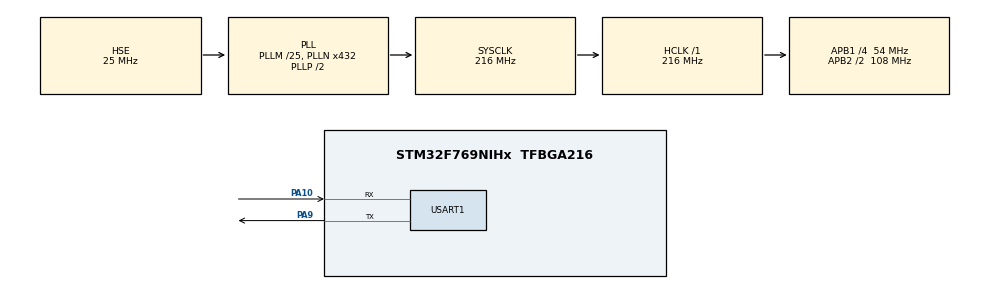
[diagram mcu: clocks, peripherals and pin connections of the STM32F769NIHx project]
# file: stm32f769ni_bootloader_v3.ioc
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Mcu.Family=STM32F7
Mcu.Name=STM32F769NIHx
Mcu.Package=TFBGA216
NVIC.PriorityGroup=NVIC_PRIORITYGROUP_4
NVIC.USART1_IRQn=true\:15\:0\:true\:false\:true\:true\:true
PA10.Mode=Asynchronous
PA10.Signal=USART1_RX
PA9.Mode=Asynchronous
PA9.Signal=USART1_TX
PH0/OSC_IN.Mode=HSE-External-Oscillator
PH0/OSC_IN.Signal=RCC_OSC_IN
PH1/OSC_OUT.Mode=HSE-External-Oscillator
PH1/OSC_OUT.Signal=RCC_OSC_OUT
ProjectManager.HeapSize=0x200
ProjectManager.StackSize=0x400
ProjectManager.TargetToolchain=MDK-ARM V5.32
RCC.AHBFreq_Value=216000000
RCC.APB1CLKDivider=RCC_HCLK_DIV4
RCC.APB1Freq_Value=54000000
RCC.APB1TimFreq_Value=108000000
RCC.APB2CLKDivider=RCC_HCLK_DIV2
RCC.APB2Freq_Value=108000000
RCC.APB2TimFreq_Value=216000000
RCC.CortexFreq_Value=216000000
RCC.HCLKFreq_Value=216000000
RCC.HSE_VALUE=25000000
RCC.HSI_VALUE=16000000
RCC.LSE_VALUE=32768
RCC.PLLM=25
RCC.PLLN=432
RCC.PLLSourceVirtual=RCC_PLLSOURCE_HSE
RCC.SYSCLKFreq_VALUE=216000000
RCC.SYSCLKSource=RCC_SYSCLKSOURCE_PLLCLK
RCC.USBFreq_Value=216000000
RCC.VCOOutputFreq_Value=432000000
USART1.VirtualMode-Asynchronous=VM_ASYNC
VP_CRC_VS_CRC.Mode=CRC_Activate
board=custom

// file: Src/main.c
/* USER CODE BEGIN Header */
/**
  ******************************************************************************
  * @file           : main.c
  * @brief          : Main program body
  ******************************************************************************
  * @attention
  *
  * <h2><center>&copy; Copyright (c) 2021 STMicroelectronics.
  * All rights reserved.</center></h2>
  *
  * This software component is licensed by ST under BSD 3-Clause license,
  * the "License"; You may not use this file except in compliance with the
  * License. You may obtain a copy of the License at:
  *                        opensource.org/licenses/BSD-3-Clause
  *
  ******************************************************************************
  */
/* USER CODE END Header */
#include "main.h"
#include "crc.h"
#include "usart.h"
#include "gpio.h"

/* USER CODE BEGIN Includes */
#include "stm32f769i_discovery.h"
#include "stdbool.h"
/* USER CODE END Includes */

void SystemClock_Config(void);

/* USER CODE BEGIN 0 */
#define MAX_DATA 256
#define FLASH_SECTOR2_BASE_ADDRESS 0x08008000U

uint8_t Rx_Data, Rx_Buffer[MAX_DATA];
volatile uint16_t Rx_Indx = 0;
bool flag_write = false;
volatile uint8_t len_to_write = 0;
volatile uint32_t mem_address = 0;

void bootloader_jump_to_user_app(void);
uint8_t execute_mem_write(uint8_t *pBuffer, uint32_t mem_address, uint32_t len);
uint8_t execute_flash_erase(uint8_t sector_number , uint8_t number_of_sector);
/* USER CODE END 0 */

int main(void)
{

  /* MCU Configuration--------------------------------------------------------*/

  /* Reset of all peripherals, Initializes the Flash interface and the Systick. */
  HAL_Init();

  /* Configure the system clock */
  SystemClock_Config();

  /* Initialize all configured peripherals */
  MX_GPIO_Init();
  MX_CRC_Init();
  MX_USART1_UART_Init();
  /* USER CODE BEGIN 2 */
	BSP_PB_Init(BUTTON_WAKEUP, BUTTON_MODE_GPIO);

	HAL_Delay(100);

  /* USER CODE END 2 */

  /* Infinite loop */
  /* USER CODE BEGIN WHILE */
	if(BSP_PB_GetState(BUTTON_WAKEUP) == 1)
	{
		while (1)
		{
    /* USER CODE END WHILE */

    /* USER CODE BEGIN 3 */
			if(flag_write == true)
			{
				//execute_mem_write(&Rx_Buffer[7], mem_address, len_to_write);

				HAL_UART_Transmit(&huart1, (uint8_t *) "1", 1, 1000);
				HAL_Delay(10);
				HAL_UART_Transmit(&huart1, (uint8_t *) "W", 1, 1000);
				/*---*/
				//flag_write = false;
			}
			HAL_Delay(100);
		}
	}
	else
	{
		bootloader_jump_to_user_app();
	}
}
  /* Infinite loop */
  /* USER CODE BEGIN WHILE */

  /* USER CODE END 3 */

void SystemClock_Config(void)
{
  RCC_OscInitTypeDef RCC_OscInitStruct = {0};
  RCC_ClkInitTypeDef RCC_ClkInitStruct = {0};
  RCC_PeriphCLKInitTypeDef PeriphClkInitStruct = {0};

  /** Configure the main internal regulator output voltage
  */
  __HAL_RCC_PWR_CLK_ENABLE();
  __HAL_PWR_VOLTAGESCALING_CONFIG(PWR_REGULATOR_VOLTAGE_SCALE1);
  /** Initializes the RCC Oscillators according to the specified parameters
  * in the RCC_OscInitTypeDef structure.
  */
  RCC_OscInitStruct.OscillatorType = RCC_OSCILLATORTYPE_HSE;
  RCC_OscInitStruct.HSEState = RCC_HSE_ON;
  RCC_OscInitStruct.PLL.PLLState = RCC_PLL_ON;
  RCC_OscInitStruct.PLL.PLLSource = RCC_PLLSOURCE_HSE;
  RCC_OscInitStruct.PLL.PLLM = 25;
  RCC_OscInitStruct.PLL.PLLN = 432;
  RCC_OscInitStruct.PLL.PLLP = RCC_PLLP_DIV2;
  RCC_OscInitStruct.PLL.PLLQ = 2;
  RCC_OscInitStruct.PLL.PLLR = 2;
  if (HAL_RCC_OscConfig(&RCC_OscInitStruct) != HAL_OK)
  {
    Error_Handler();
  }
  /** Activate the Over-Drive mode
  */
  if (HAL_PWREx_EnableOverDrive() != HAL_OK)
  {
    Error_Handler();
  }
  /** Initializes the CPU, AHB and APB buses clocks
  */
  RCC_ClkInitStruct.ClockType = RCC_CLOCKTYPE_HCLK|RCC_CLOCKTYPE_SYSCLK
                              |RCC_CLOCKTYPE_PCLK1|RCC_CLOCKTYPE_PCLK2;
  RCC_ClkInitStruct.SYSCLKSource = RCC_SYSCLKSOURCE_PLLCLK;
  RCC_ClkInitStruct.AHBCLKDivider = RCC_SYSCLK_DIV1;
  RCC_ClkInitStruct.APB1CLKDivider = RCC_HCLK_DIV4;
  RCC_ClkInitStruct.APB2CLKDivider = RCC_HCLK_DIV2;

  if (HAL_RCC_ClockConfig(&RCC_ClkInitStruct, FLASH_LATENCY_7) != HAL_OK)
  {
    Error_Handler();
  }
  PeriphClkInitStruct.PeriphClockSelection = RCC_PERIPHCLK_USART1;
  PeriphClkInitStruct.Usart1ClockSelection = RCC_USART1CLKSOURCE_PCLK2;
  if (HAL_RCCEx_PeriphCLKConfig(&PeriphClkInitStruct) != HAL_OK)
  {
    Error_Handler();
  }
}

void Error_Handler(void)
{
  __disable_irq();
  while (1)
  {
  }
}

/************************ (C) COPYRIGHT STMicroelectronics *****END OF FILE****/
